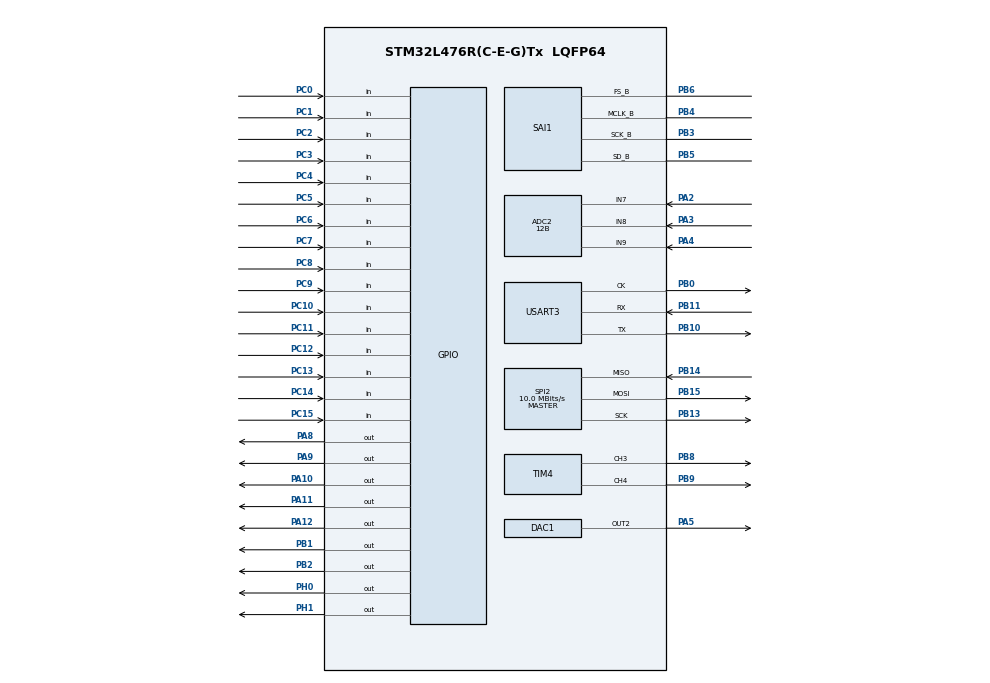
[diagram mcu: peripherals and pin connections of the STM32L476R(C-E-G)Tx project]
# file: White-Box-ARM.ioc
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ADC2.Channel-69\#ChannelRegularConversion=ADC_CHANNEL_9
ADC2.ClockPrescaler=ADC_CLOCK_ASYNC_DIV12
ADC2.ContinuousConvMode=ENABLE
ADC2.DMAContinuousRequests=DISABLE
ADC2.DataAlign=ADC_DATAALIGN_RIGHT
ADC2.DiscontinuousConvMode=DISABLE
ADC2.EOCSelection=ADC_EOC_SINGLE_CONV
ADC2.EnableAnalogWatchDog1=false
ADC2.EnableAnalogWatchDog2=false
ADC2.EnableAnalogWatchDog3=false
ADC2.EnableInjectedConversion=DISABLE
ADC2.EnableRegularConversion=ENABLE
ADC2.ExternalTrigConv=ADC_SOFTWARE_START
ADC2.ExternalTrigConvEdge=ADC_EXTERNALTRIGCONVEDGE_NONE
ADC2.LowPowerAutoWait=DISABLE
ADC2.NbrOfConversion=1
ADC2.NbrOfConversionFlag=1
ADC2.OffsetNumber-69\#ChannelRegularConversion=ADC_OFFSET_NONE
ADC2.Overrun=ADC_OVR_DATA_PRESERVED
ADC2.OversamplingMode=DISABLE
ADC2.Rank-69\#ChannelRegularConversion=1
ADC2.Resolution=ADC_RESOLUTION_12B
ADC2.SamplingTime-69\#ChannelRegularConversion=ADC_SAMPLETIME_2CYCLES_5
ADC2.ScanConvMode=ADC_SCAN_DISABLE
DAC1.DAC_Channel-DAC_OUT2=DAC_CHANNEL_2
Mcu.Family=STM32L4
Mcu.Name=STM32L476R(C-E-G)Tx
Mcu.Package=LQFP64
NVIC.ADC1_2_IRQn=true\:0\:0\:false\:false\:true\:true
NVIC.PriorityGroup=NVIC_PRIORITYGROUP_4
NVIC.TIM4_IRQn=true\:0\:0\:false\:false\:true\:true
NVIC.TIM6_DAC_IRQn=true\:0\:0\:false\:false\:true\:true
PA10.Signal=GPIO_Output
PA11.Signal=GPIO_Output
PA12.Signal=GPIO_Output
PA2.Signal=ADCx_IN7
PA3.Signal=ADCx_IN8
PA4.Signal=ADCx_IN9
PA5.Signal=COMP_DAC12_group
PA8.Signal=GPIO_Output
PA9.Signal=GPIO_Output
PB0.Mode=Synchronous
PB0.Signal=USART3_CK
PB1.GPIO_Speed=GPIO_SPEED_FREQ_LOW
PB1.PinState=GPIO_PIN_RESET
PB1.Signal=GPIO_Output
PB10.Mode=Synchronous
PB10.Signal=USART3_TX
PB11.Mode=Synchronous
PB11.Signal=USART3_RX
PB13.Mode=Full_Duplex_Master
PB13.Signal=SPI2_SCK
PB14.Mode=Full_Duplex_Master
PB14.Signal=SPI2_MISO
PB15.Mode=Full_Duplex_Master
PB15.Signal=SPI2_MOSI
PB2.GPIO_Speed=GPIO_SPEED_FREQ_LOW
PB2.PinState=GPIO_PIN_RESET
PB2.Signal=GPIO_Output
PB3\ (JTDO-TRACESWO).Mode=SAI_B_MasterWithClock
PB3\ (JTDO-TRACESWO).Signal=SAI1_SCK_B
PB4\ (NJTRST).Mode=SAI_B_MasterWithClock
PB4\ (NJTRST).Signal=SAI1_MCLK_B
PB5.Mode=SAI_B_MasterWithClock
PB5.Signal=SAI1_SD_B
PB6.Mode=SAI_B_MasterWithClock
PB6.Signal=SAI1_FS_B
PB8.Signal=S_TIM4_CH3
PB9.Signal=S_TIM4_CH4
PC0.Signal=GPIO_Input
PC1.GPIO_PuPd=GPIO_PULLUP
PC1.Signal=GPIO_Input
PC10.Signal=GPIO_Input
PC11.Signal=GPIO_Input
PC12.Signal=GPIO_Input
PC13.Signal=GPIO_Input
PC14-OSC32_IN\ (PC14).Signal=GPIO_Input
PC15-OSC32_OUT\ (PC15).Signal=GPIO_Input
PC2.GPIO_PuPd=GPIO_PULLUP
PC2.Signal=GPIO_Input
PC3.GPIO_PuPd=GPIO_PULLUP
PC3.Signal=GPIO_Input
PC4.GPIO_PuPd=GPIO_PULLUP
PC4.Signal=GPIO_Input
PC5.GPIO_PuPd=GPIO_PULLUP
PC5.Signal=GPIO_Input
PC6.GPIO_PuPd=GPIO_PULLUP
PC6.Signal=GPIO_Input
PC7.GPIO_PuPd=GPIO_PULLUP
PC7.Signal=GPIO_Input
PC8.Signal=GPIO_Input
PC9.Signal=GPIO_Input
PH0-OSC_IN\ (PH0).GPIO_Speed=GPIO_SPEED_FREQ_LOW
PH0-OSC_IN\ (PH0).PinState=GPIO_PIN_RESET
PH0-OSC_IN\ (PH0).Signal=GPIO_Output
PH1-OSC_OUT\ (PH1).GPIO_Speed=GPIO_SPEED_FREQ_LOW
PH1-OSC_OUT\ (PH1).PinState=GPIO_PIN_RESET
PH1-OSC_OUT\ (PH1).Signal=GPIO_Output
ProjectManager.HeapSize=0x200
ProjectManager.StackSize=0x400
ProjectManager.TargetToolchain=Makefile
RCC.ADCFreq_Value=8000000
RCC.AHBFreq_Value=80000000
RCC.APB1CLKDivider=RCC_HCLK_DIV4
RCC.APB1Freq_Value=20000000
RCC.APB1TimFreq_Value=40000000
RCC.APB2CLKDivider=RCC_HCLK_DIV4
RCC.APB2Freq_Value=20000000
RCC.APB2TimFreq_Value=40000000
RCC.CortexFreq_Value=80000000
RCC.HCLKFreq_Value=80000000
RCC.HSE_VALUE=8000000
RCC.HSI_VALUE=16000000
RCC.LPTIM2CLockSelection=RCC_LPTIM2CLKSOURCE_HSI
RCC.LSE_VALUE=32768
RCC.MSI_VALUE=4000000
RCC.PLLN=40
RCC.PLLSAI1N=16
RCC.PLLSAI1R=RCC_PLLR_DIV8
RCC.PLLSAI2N=28
RCC.SAI1CLockSelection=RCC_SAI1CLKSOURCE_PLLSAI2
RCC.SYSCLKFreq_VALUE=80000000
RCC.SYSCLKSource=RCC_SYSCLKSOURCE_PLLCLK
RCC.USBFreq_Value=32000000
RCC.VCOOutputFreq_Value=160000000
SAI1.AudioFrequency-SAI_B_MasterWithClock=SAI_AUDIO_FREQUENCY_44K
SAI1.ErrorAudioFreq-SAI_B_MasterWithClock=-81.39 %
SAI1.InitProtocol-SAI_B_MasterWithClock=Enable
SAI1.Instance-SAI_B_MasterWithClock=SAI$Index_Block_B
SAI1.MClockEnable-SAI_B_MasterWithClock=SAI_MASTERCLOCK_ENABLE
SAI1.RealAudioFreq-SAI_B_MasterWithClock=35.714 KHz
SAI1.Synchro-SAI_B_MasterWithClock=SAI_ASYNCHRONOUS
SAI1.VirtualMode-SAI_B_MasterWithClock=VM_MASTER
SAI1.VirtualProtocol-SAI_B_BASIC=VM_BASIC_PROTOCOL
SH.ADCx_IN7.0=ADC2_IN7,IN7-Differential
SH.ADCx_IN8.0=ADC2_IN8,IN7-Differential
SH.ADCx_IN9.0=ADC2_IN9,IN9-Single-Ended
SH.COMP_DAC12_group.0=DAC1_OUT2,DAC_OUT2
SH.S_TIM4_CH3.0=TIM4_CH3,PWM Generation3 CH3
SH.S_TIM4_CH4.0=TIM4_CH4,PWM Generation4 CH4
SPI2.CalculateBaudRate=10.0 MBits/s
SPI2.Direction=SPI_DIRECTION_2LINES
SPI2.Mode=SPI_MODE_MASTER
SPI2.VirtualType=VM_MASTER
TIM4.AutoReloadPreload=TIM_AUTORELOAD_PRELOAD_ENABLE
TIM4.Channel-PWM\ Generation3\ CH3=TIM_CHANNEL_3
TIM4.Channel-PWM\ Generation4\ CH4=TIM_CHANNEL_4
TIM4.Pulse-PWM\ Generation3\ CH3=13107
TIM4.Pulse-PWM\ Generation4\ CH4=13107
TIM6.Period=40
TIM6.Prescaler=1000
USART3.VirtualMode-Synchronous=VM_SYNC
VP_SAI1_VP_$IpInstance_SAIB_SAI_BASIC.Mode=SAI_B_BASIC
VP_TIM6_VS_ClockSourceINT.Mode=Enable_Timer
board=White-Box-ARM

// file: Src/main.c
/**
  ******************************************************************************
  * File Name          : main.c
  * Description        : Main program body
  ******************************************************************************
  ** This notice applies to any and all portions of this file
  * that are not between comment pairs USER CODE BEGIN and
  * USER CODE END. Other portions of this file, whether
  * inserted by the user or by software development tools
  * are owned by their respective copyright owners.
  *
  * COPYRIGHT(c) 2017 STMicroelectronics
  *
  * Redistribution and use in source and binary forms, with or without modification,
  * are permitted provided that the following conditions are met:
  *   1. Redistributions of source code must retain the above copyright notice,
  *      this list of conditions and the following disclaimer.
  *   2. Redistributions in binary form must reproduce the above copyright notice,
  *      this list of conditions and the following disclaimer in the documentation
  *      and/or other materials provided with the distribution.
  *   3. Neither the name of STMicroelectronics nor the names of its contributors
  *      may be used to endorse or promote products derived from this software
  *      without specific prior written permission.
  *
  * THIS SOFTWARE IS PROVIDED BY THE COPYRIGHT HOLDERS AND CONTRIBUTORS "AS IS"
  * AND ANY EXPRESS OR IMPLIED WARRANTIES, INCLUDING, BUT NOT LIMITED TO, THE
  * IMPLIED WARRANTIES OF MERCHANTABILITY AND FITNESS FOR A PARTICULAR PURPOSE ARE
  * DISCLAIMED. IN NO EVENT SHALL THE COPYRIGHT HOLDER OR CONTRIBUTORS BE LIABLE
  * FOR ANY DIRECT, INDIRECT, INCIDENTAL, SPECIAL, EXEMPLARY, OR CONSEQUENTIAL
  * DAMAGES (INCLUDING, BUT NOT LIMITED TO, PROCUREMENT OF SUBSTITUTE GOODS OR
  * SERVICES; LOSS OF USE, DATA, OR PROFITS; OR BUSINESS INTERRUPTION) HOWEVER
  * CAUSED AND ON ANY THEORY OF LIABILITY, WHETHER IN CONTRACT, STRICT LIABILITY,
  * OR TORT (INCLUDING NEGLIGENCE OR OTHERWISE) ARISING IN ANY WAY OUT OF THE USE
  * OF THIS SOFTWARE, EVEN IF ADVISED OF THE POSSIBILITY OF SUCH DAMAGE.
  *
  ******************************************************************************
  */
#include "main.h"
#include "stm32l4xx_hal.h"

/* USER CODE BEGIN Includes */
#include "math.h"
#include "lcd.h"
#include "effects.h"
/* USER CODE END Includes */

SAI_HandleTypeDef hsai_BlockB1;

TIM_HandleTypeDef htim6;

/* USER CODE BEGIN PV */
/* Private variables ---------------------------------------------------------*/

/* USER CODE END PV */

void SystemClock_Config(void);
static void MX_GPIO_Init(void);
static void MX_SAI1_Init(void);
static void MX_TIM4_Init(void);
static void MX_ADC2_Init(void);
static void MX_SPI2_Init(void);
static void MX_USART3_Init(void);
static void MX_DAC1_Init(void);
static void MX_TIM6_Init(void);

/* USER CODE BEGIN PFP */
/* Private function prototypes -----------------------------------------------*/

/* USER CODE END PFP */

int main(void)
{

  /* MCU Configuration----------------------------------------------------------*/

  /* Reset of all peripherals, Initializes the Flash interface and the Systick. */
  HAL_Init();

  /* Configure the system clock */
  SystemClock_Config();

  /* Initialize all configured peripherals */
  MX_GPIO_Init();
  MX_SAI1_Init();
  MX_TIM4_Init();
  MX_ADC2_Init();
  MX_SPI2_Init();
  MX_USART3_Init();
  MX_DAC1_Init();
  MX_TIM6_Init();

  /* USER CODE BEGIN 2 */
  init_LCD();
  effects_init();

  unsigned int i;
  char line1[] = "current count:      ";
  for(i = 0; i < LCD_line_length; i++){
    LCD_write_data(line1[i]);
  }

  while (1) {
    LCD_write_integer(1, 15, i, 5);

  }
  /* USER CODE END 2 */

  /* Infinite loop */
  while (1)
  {

  }

}

/** System Clock Configuration
*/
void SystemClock_Config(void)
{

  LL_FLASH_SetLatency(LL_FLASH_LATENCY_3);

  if(LL_FLASH_GetLatency() != LL_FLASH_LATENCY_3)
  {
  Error_Handler();
  }
  LL_PWR_SetRegulVoltageScaling(LL_PWR_REGU_VOLTAGE_SCALE1);

  LL_RCC_MSI_Enable();

   /* Wait till MSI is ready */
  while(LL_RCC_MSI_IsReady() != 1)
  {

  }
  LL_RCC_MSI_EnableRangeSelection();

  LL_RCC_MSI_SetRange(LL_RCC_MSIRANGE_6);

  LL_RCC_MSI_SetCalibTrimming(0);

  LL_RCC_PLL_ConfigDomain_SYS(LL_RCC_PLLSOURCE_MSI, LL_RCC_PLLM_DIV_1, 40, LL_RCC_PLLR_DIV_2);

  LL_RCC_PLL_EnableDomain_SYS();

  LL_RCC_PLL_Enable();

   /* Wait till PLL is ready */
  while(LL_RCC_PLL_IsReady() != 1)
  {

  }
  LL_RCC_PLLSAI1_ConfigDomain_ADC(LL_RCC_PLLSOURCE_MSI, LL_RCC_PLLM_DIV_1, 16, LL_RCC_PLLSAI1R_DIV_8);

  LL_RCC_PLLSAI1_EnableDomain_ADC();

  LL_RCC_PLLSAI1_Enable();

   /* Wait till PLLSAI1 is ready */
  while(LL_RCC_PLLSAI1_IsReady() != 1)
  {

  }
  LL_RCC_PLLSAI2_ConfigDomain_SAI(LL_RCC_PLLSOURCE_MSI, LL_RCC_PLLM_DIV_1, 28, LL_RCC_PLLSAI2P_DIV_7);

  LL_RCC_PLLSAI2_EnableDomain_SAI();

  LL_RCC_PLLSAI2_Enable();

   /* Wait till PLLSAI2 is ready */
  while(LL_RCC_PLLSAI2_IsReady() != 1)
  {

  }
  LL_RCC_SetSysClkSource(LL_RCC_SYS_CLKSOURCE_PLL);

   /* Wait till System clock is ready */
  while(LL_RCC_GetSysClkSource() != LL_RCC_SYS_CLKSOURCE_STATUS_PLL)
  {

  }
  LL_RCC_SetAHBPrescaler(LL_RCC_SYSCLK_DIV_1);

  LL_RCC_SetAPB1Prescaler(LL_RCC_APB1_DIV_4);

  LL_RCC_SetAPB2Prescaler(LL_RCC_APB2_DIV_4);

  LL_Init1msTick(80000000);

  LL_SYSTICK_SetClkSource(LL_SYSTICK_CLKSOURCE_HCLK);

  LL_SetSystemCoreClock(80000000);

  LL_RCC_SetUSARTClockSource(LL_RCC_USART3_CLKSOURCE_PCLK1);

  LL_RCC_SetSAIClockSource(LL_RCC_SAI1_CLKSOURCE_PLLSAI2);

  LL_RCC_SetADCClockSource(LL_RCC_ADC_CLKSOURCE_PLLSAI1);

  /* SysTick_IRQn interrupt configuration */
  NVIC_SetPriority(SysTick_IRQn, NVIC_EncodePriority(NVIC_GetPriorityGrouping(),0, 0));
}

/* ADC2 init function */
static void MX_ADC2_Init(void)
{

  LL_ADC_InitTypeDef ADC_InitStruct;
  LL_ADC_REG_InitTypeDef ADC_REG_InitStruct;
  LL_ADC_CommonInitTypeDef ADC_CommonInitStruct;

  LL_GPIO_InitTypeDef GPIO_InitStruct;

  /* Peripheral clock enable */
  LL_AHB2_GRP1_EnableClock(LL_AHB2_GRP1_PERIPH_ADC);

  /**ADC2 GPIO Configuration
  PA2   ------> ADC2_IN7
  PA3   ------> ADC2_IN8
  PA4   ------> ADC2_IN9
  */
  GPIO_InitStruct.Pin = LL_GPIO_PIN_2|LL_GPIO_PIN_3|LL_GPIO_PIN_4;
  GPIO_InitStruct.Mode = LL_GPIO_MODE_ANALOG;
  GPIO_InitStruct.Pull = LL_GPIO_PULL_NO;
  LL_GPIO_Init(GPIOA, &GPIO_InitStruct);

  LL_GPIO_EnablePinAnalogControl(GPIOA, LL_GPIO_PIN_2|LL_GPIO_PIN_3|LL_GPIO_PIN_4);

  /* ADC2 interrupt Init */
  NVIC_SetPriority(ADC1_2_IRQn, NVIC_EncodePriority(NVIC_GetPriorityGrouping(),0, 0));
  NVIC_EnableIRQ(ADC1_2_IRQn);

    /**Common config
    */
  ADC_InitStruct.Resolution = LL_ADC_RESOLUTION_12B;
  ADC_InitStruct.DataAlignment = LL_ADC_DATA_ALIGN_RIGHT;
  ADC_InitStruct.LowPowerMode = LL_ADC_LP_MODE_NONE;
  LL_ADC_Init(ADC2, &ADC_InitStruct);

  ADC_REG_InitStruct.TriggerSource = LL_ADC_REG_TRIG_SOFTWARE;
  ADC_REG_InitStruct.SequencerLength = LL_ADC_REG_SEQ_SCAN_DISABLE;
  ADC_REG_InitStruct.SequencerDiscont = LL_ADC_REG_SEQ_DISCONT_DISABLE;
  ADC_REG_InitStruct.ContinuousMode = LL_ADC_REG_CONV_CONTINUOUS;
  ADC_REG_InitStruct.DMATransfer = LL_ADC_REG_DMA_TRANSFER_LIMITED;
  ADC_REG_InitStruct.Overrun = LL_ADC_REG_OVR_DATA_PRESERVED;
  LL_ADC_REG_Init(ADC2, &ADC_REG_InitStruct);

  LL_ADC_SetOverSamplingScope(ADC2, LL_ADC_OVS_DISABLE);

  ADC_CommonInitStruct.CommonClock = LL_ADC_CLOCK_ASYNC_DIV12;
  LL_ADC_CommonInit(__LL_ADC_COMMON_INSTANCE(ADC2), &ADC_CommonInitStruct);

  LL_ADC_EnableIT_EOC(ADC2);

  LL_ADC_DisableIT_EOS(ADC2);

    /**Configure Regular Channel
    */
  LL_ADC_REG_SetSequencerRanks(ADC2, LL_ADC_REG_RANK_1, LL_ADC_CHANNEL_9);

  LL_ADC_SetChannelSamplingTime(ADC2, LL_ADC_CHANNEL_9, LL_ADC_SAMPLINGTIME_2CYCLES_5);

  LL_ADC_SetChannelSingleDiff(ADC2, LL_ADC_CHANNEL_9, LL_ADC_SINGLE_ENDED);

}

/* DAC1 init function */
static void MX_DAC1_Init(void)
{

  LL_DAC_InitTypeDef DAC_InitStruct;

  LL_GPIO_InitTypeDef GPIO_InitStruct;

  /* Peripheral clock enable */
  LL_APB1_GRP1_EnableClock(LL_APB1_GRP1_PERIPH_DAC1);

  /**DAC1 GPIO Configuration
  PA5   ------> DAC1_OUT2
  */
  GPIO_InitStruct.Pin = LL_GPIO_PIN_5;
  GPIO_InitStruct.Mode = LL_GPIO_MODE_ANALOG;
  GPIO_InitStruct.Pull = LL_GPIO_PULL_NO;
  LL_GPIO_Init(GPIOA, &GPIO_InitStruct);

  /* DAC1 interrupt Init */
  NVIC_SetPriority(TIM6_DAC_IRQn, NVIC_EncodePriority(NVIC_GetPriorityGrouping(),0, 0));
  NVIC_EnableIRQ(TIM6_DAC_IRQn);

    /**DAC channel OUT2 config
    */
  DAC_InitStruct.TriggerSource = LL_DAC_TRIG_SOFTWARE;
  DAC_InitStruct.WaveAutoGeneration = LL_DAC_WAVE_AUTO_GENERATION_NONE;
  DAC_InitStruct.OutputBuffer = LL_DAC_OUTPUT_BUFFER_ENABLE;
  DAC_InitStruct.OutputConnection = LL_DAC_OUTPUT_CONNECT_GPIO;
  DAC_InitStruct.OutputMode = LL_DAC_OUTPUT_MODE_NORMAL;
  LL_DAC_Init(DAC1, LL_DAC_CHANNEL_2, &DAC_InitStruct);

  LL_DAC_DisableTrigger(DAC1, LL_DAC_CHANNEL_2);

}

/* SAI1 init function */
static void MX_SAI1_Init(void)
{

  hsai_BlockB1.Instance = SAI1_Block_B;
  hsai_BlockB1.Init.AudioMode = SAI_MODEMASTER_TX;
  hsai_BlockB1.Init.Synchro = SAI_ASYNCHRONOUS;
  hsai_BlockB1.Init.OutputDrive = SAI_OUTPUTDRIVE_DISABLE;
  hsai_BlockB1.Init.NoDivider = SAI_MASTERDIVIDER_ENABLE;
  hsai_BlockB1.Init.FIFOThreshold = SAI_FIFOTHRESHOLD_EMPTY;
  hsai_BlockB1.Init.AudioFrequency = SAI_AUDIO_FREQUENCY_44K;
  hsai_BlockB1.Init.SynchroExt = SAI_SYNCEXT_DISABLE;
  hsai_BlockB1.Init.MonoStereoMode = SAI_STEREOMODE;
  hsai_BlockB1.Init.CompandingMode = SAI_NOCOMPANDING;
  hsai_BlockB1.Init.TriState = SAI_OUTPUT_NOTRELEASED;
  if (HAL_SAI_InitProtocol(&hsai_BlockB1, SAI_I2S_STANDARD, SAI_PROTOCOL_DATASIZE_16BIT, 2) != HAL_OK)
  {
    _Error_Handler(__FILE__, __LINE__);
  }

}

/* SPI2 init function */
static void MX_SPI2_Init(void)
{

  LL_SPI_InitTypeDef SPI_InitStruct;

  LL_GPIO_InitTypeDef GPIO_InitStruct;

  /* Peripheral clock enable */
  LL_APB1_GRP1_EnableClock(LL_APB1_GRP1_PERIPH_SPI2);

  /**SPI2 GPIO Configuration
  PB13   ------> SPI2_SCK
  PB14   ------> SPI2_MISO
  PB15   ------> SPI2_MOSI
  */
  GPIO_InitStruct.Pin = LL_GPIO_PIN_13|LL_GPIO_PIN_14|LL_GPIO_PIN_15;
  GPIO_InitStruct.Mode = LL_GPIO_MODE_ALTERNATE;
  GPIO_InitStruct.Speed = LL_GPIO_SPEED_FREQ_VERY_HIGH;
  GPIO_InitStruct.OutputType = LL_GPIO_OUTPUT_PUSHPULL;
  GPIO_InitStruct.Pull = LL_GPIO_PULL_NO;
  GPIO_InitStruct.Alternate = LL_GPIO_AF_5;
  LL_GPIO_Init(GPIOB, &GPIO_InitStruct);

  /* SPI2 parameter configuration*/
  SPI_InitStruct.TransferDirection = LL_SPI_FULL_DUPLEX;
  SPI_InitStruct.Mode = LL_SPI_MODE_MASTER;
  SPI_InitStruct.DataWidth = LL_SPI_DATAWIDTH_4BIT;
  SPI_InitStruct.ClockPolarity = LL_SPI_POLARITY_LOW;
  SPI_InitStruct.ClockPhase = LL_SPI_PHASE_1EDGE;
  SPI_InitStruct.NSS = LL_SPI_NSS_SOFT;
  SPI_InitStruct.BaudRate = LL_SPI_BAUDRATEPRESCALER_DIV2;
  SPI_InitStruct.BitOrder = LL_SPI_MSB_FIRST;
  SPI_InitStruct.CRCCalculation = LL_SPI_CRCCALCULATION_DISABLE;
  SPI_InitStruct.CRCPoly = 7;
  LL_SPI_Init(SPI2, &SPI_InitStruct);

  LL_SPI_SetStandard(SPI2, LL_SPI_PROTOCOL_MOTOROLA);

  LL_SPI_EnableNSSPulseMgt(SPI2);

}

/* TIM4 init function */
static void MX_TIM4_Init(void)
{

  LL_TIM_InitTypeDef TIM_InitStruct;
  LL_TIM_OC_InitTypeDef TIM_OC_InitStruct;

  LL_GPIO_InitTypeDef GPIO_InitStruct;

  /* Peripheral clock enable */
  LL_APB1_GRP1_EnableClock(LL_APB1_GRP1_PERIPH_TIM4);

  /* TIM4 interrupt Init */
  NVIC_SetPriority(TIM4_IRQn, NVIC_EncodePriority(NVIC_GetPriorityGrouping(),0, 0));
  NVIC_EnableIRQ(TIM4_IRQn);

  TIM_InitStruct.Prescaler = 0;
  TIM_InitStruct.CounterMode = LL_TIM_COUNTERMODE_UP;
  TIM_InitStruct.Autoreload = 0;
  TIM_InitStruct.ClockDivision = LL_TIM_CLOCKDIVISION_DIV1;
  LL_TIM_Init(TIM4, &TIM_InitStruct);

  LL_TIM_EnableARRPreload(TIM4);

  LL_TIM_OC_EnablePreload(TIM4, LL_TIM_CHANNEL_CH3);

  TIM_OC_InitStruct.OCMode = LL_TIM_OCMODE_PWM1;
  TIM_OC_InitStruct.OCState = LL_TIM_OCSTATE_DISABLE;
  TIM_OC_InitStruct.OCNState = LL_TIM_OCSTATE_DISABLE;
  TIM_OC_InitStruct.CompareValue = 13107;
  TIM_OC_InitStruct.OCPolarity = LL_TIM_OCPOLARITY_HIGH;
  LL_TIM_OC_Init(TIM4, LL_TIM_CHANNEL_CH3, &TIM_OC_InitStruct);

  LL_TIM_OC_DisableFast(TIM4, LL_TIM_CHANNEL_CH3);

  LL_TIM_OC_EnablePreload(TIM4, LL_TIM_CHANNEL_CH4);

  TIM_OC_InitStruct.OCState = LL_TIM_OCSTATE_DISABLE;
  TIM_OC_InitStruct.OCNState = LL_TIM_OCSTATE_DISABLE;
  LL_TIM_OC_Init(TIM4, LL_TIM_CHANNEL_CH4, &TIM_OC_InitStruct);

  LL_TIM_OC_DisableFast(TIM4, LL_TIM_CHANNEL_CH4);

  LL_TIM_SetOCRefClearInputSource(TIM4, LL_TIM_OCREF_CLR_INT_NC);

  LL_TIM_DisableExternalClock(TIM4);

  LL_TIM_ConfigETR(TIM4, LL_TIM_ETR_POLARITY_NONINVERTED, LL_TIM_ETR_PRESCALER_DIV1, LL_TIM_ETR_FILTER_FDIV1);

  LL_TIM_SetTriggerOutput(TIM4, LL_TIM_TRGO_RESET);

  LL_TIM_DisableMasterSlaveMode(TIM4);

  /**TIM4 GPIO Configuration
  PB8   ------> TIM4_CH3
  PB9   ------> TIM4_CH4
  */
  GPIO_InitStruct.Pin = LL_GPIO_PIN_8|LL_GPIO_PIN_9;
  GPIO_InitStruct.Mode = LL_GPIO_MODE_ALTERNATE;
  GPIO_InitStruct.Speed = LL_GPIO_SPEED_FREQ_LOW;
  GPIO_InitStruct.OutputType = LL_GPIO_OUTPUT_PUSHPULL;
  GPIO_InitStruct.Pull = LL_GPIO_PULL_NO;
  GPIO_InitStruct.Alternate = LL_GPIO_AF_2;
  LL_GPIO_Init(GPIOB, &GPIO_InitStruct);

}

/* TIM6 init function */
static void MX_TIM6_Init(void)
{

  TIM_MasterConfigTypeDef sMasterConfig;

  htim6.Instance = TIM6;
  htim6.Init.Prescaler = 1000;
  htim6.Init.CounterMode = TIM_COUNTERMODE_UP;
  htim6.Init.Period = 40;
  htim6.Init.AutoReloadPreload = TIM_AUTORELOAD_PRELOAD_DISABLE;
  if (HAL_TIM_Base_Init(&htim6) != HAL_OK)
  {
    _Error_Handler(__FILE__, __LINE__);
  }

  sMasterConfig.MasterOutputTrigger = TIM_TRGO_RESET;
  sMasterConfig.MasterSlaveMode = TIM_MASTERSLAVEMODE_DISABLE;
  if (HAL_TIMEx_MasterConfigSynchronization(&htim6, &sMasterConfig) != HAL_OK)
  {
    _Error_Handler(__FILE__, __LINE__);
  }

}

/* USART3 init function */
static void MX_USART3_Init(void)
{

  LL_USART_InitTypeDef USART_InitStruct;
  LL_USART_ClockInitTypeDef USART_ClockInitStruct;

  LL_GPIO_InitTypeDef GPIO_InitStruct;

  /* Peripheral clock enable */
  LL_APB1_GRP1_EnableClock(LL_APB1_GRP1_PERIPH_USART3);

  /**USART3 GPIO Configuration
  PB0   ------> USART3_CK
  PB10   ------> USART3_TX
  PB11   ------> USART3_RX
  */
  GPIO_InitStruct.Pin = LL_GPIO_PIN_0|LL_GPIO_PIN_10|LL_GPIO_PIN_11;
  GPIO_InitStruct.Mode = LL_GPIO_MODE_ALTERNATE;
  GPIO_InitStruct.Speed = LL_GPIO_SPEED_FREQ_VERY_HIGH;
  GPIO_InitStruct.OutputType = LL_GPIO_OUTPUT_PUSHPULL;
  GPIO_InitStruct.Pull = LL_GPIO_PULL_NO;
  GPIO_InitStruct.Alternate = LL_GPIO_AF_7;
  LL_GPIO_Init(GPIOB, &GPIO_InitStruct);

  USART_InitStruct.BaudRate = 115200;
  USART_InitStruct.DataWidth = LL_USART_DATAWIDTH_7B;
  USART_InitStruct.StopBits = LL_USART_STOPBITS_1;
  USART_InitStruct.Parity = LL_USART_PARITY_NONE;
  USART_InitStruct.TransferDirection = LL_USART_DIRECTION_TX_RX;
  USART_InitStruct.OverSampling = LL_USART_OVERSAMPLING_8;

  LL_USART_Init(USART3, &USART_InitStruct);

  USART_ClockInitStruct.ClockPolarity = LL_USART_POLARITY_LOW;
  USART_ClockInitStruct.ClockPhase = LL_USART_PHASE_1EDGE;
  USART_ClockInitStruct.LastBitClockPulse = LL_USART_LASTCLKPULSE_NO_OUTPUT;
  LL_USART_ClockInit(USART3, &USART_ClockInitStruct);

  LL_USART_ConfigSyncMode(USART3);

  LL_USART_Enable(USART3);

}

/** Configure pins as
        * Analog
        * Input
        * Output
        * EVENT_OUT
        * EXTI
*/
static void MX_GPIO_Init(void)
{

  LL_GPIO_InitTypeDef GPIO_InitStruct;

  /* GPIO Ports Clock Enable */
  LL_AHB2_GRP1_EnableClock(LL_AHB2_GRP1_PERIPH_GPIOC);
  LL_AHB2_GRP1_EnableClock(LL_AHB2_GRP1_PERIPH_GPIOH);
  LL_AHB2_GRP1_EnableClock(LL_AHB2_GRP1_PERIPH_GPIOA);
  LL_AHB2_GRP1_EnableClock(LL_AHB2_GRP1_PERIPH_GPIOB);

  /**/
  LL_GPIO_ResetOutputPin(GPIOH, LL_GPIO_PIN_0|LL_GPIO_PIN_1);

  /**/
  LL_GPIO_ResetOutputPin(GPIOB, LL_GPIO_PIN_1|LL_GPIO_PIN_2);

  /**/
  LL_GPIO_ResetOutputPin(GPIOA, LL_GPIO_PIN_8|LL_GPIO_PIN_9|LL_GPIO_PIN_10|LL_GPIO_PIN_11
                          |LL_GPIO_PIN_12);

  /**/
  GPIO_InitStruct.Pin = LL_GPIO_PIN_13|LL_GPIO_PIN_14|LL_GPIO_PIN_15|LL_GPIO_PIN_0
                          |LL_GPIO_PIN_8|LL_GPIO_PIN_9|LL_GPIO_PIN_10|LL_GPIO_PIN_11
                          |LL_GPIO_PIN_12;
  GPIO_InitStruct.Mode = LL_GPIO_MODE_INPUT;
  GPIO_InitStruct.Pull = LL_GPIO_PULL_NO;
  LL_GPIO_Init(GPIOC, &GPIO_InitStruct);

  /**/
  GPIO_InitStruct.Pin = LL_GPIO_PIN_0|LL_GPIO_PIN_1;
  GPIO_InitStruct.Mode = LL_GPIO_MODE_OUTPUT;
  GPIO_InitStruct.Speed = LL_GPIO_SPEED_FREQ_LOW;
  GPIO_InitStruct.OutputType = LL_GPIO_OUTPUT_PUSHPULL;
  GPIO_InitStruct.Pull = LL_GPIO_PULL_NO;
  LL_GPIO_Init(GPIOH, &GPIO_InitStruct);

  /**/
  GPIO_InitStruct.Pin = LL_GPIO_PIN_1|LL_GPIO_PIN_2|LL_GPIO_PIN_3|LL_GPIO_PIN_4
                          |LL_GPIO_PIN_5|LL_GPIO_PIN_6|LL_GPIO_PIN_7;
  GPIO_InitStruct.Mode = LL_GPIO_MODE_INPUT;
  GPIO_InitStruct.Pull = LL_GPIO_PULL_UP;
  LL_GPIO_Init(GPIOC, &GPIO_InitStruct);

  /**/
  GPIO_InitStruct.Pin = LL_GPIO_PIN_1|LL_GPIO_PIN_2;
  GPIO_InitStruct.Mode = LL_GPIO_MODE_OUTPUT;
  GPIO_InitStruct.Speed = LL_GPIO_SPEED_FREQ_LOW;
  GPIO_InitStruct.OutputType = LL_GPIO_OUTPUT_PUSHPULL;
  GPIO_InitStruct.Pull = LL_GPIO_PULL_NO;
  LL_GPIO_Init(GPIOB, &GPIO_InitStruct);

  /**/
  GPIO_InitStruct.Pin = LL_GPIO_PIN_8|LL_GPIO_PIN_9|LL_GPIO_PIN_10|LL_GPIO_PIN_11
                          |LL_GPIO_PIN_12;
  GPIO_InitStruct.Mode = LL_GPIO_MODE_OUTPUT;
  GPIO_InitStruct.Speed = LL_GPIO_SPEED_FREQ_LOW;
  GPIO_InitStruct.OutputType = LL_GPIO_OUTPUT_PUSHPULL;
  GPIO_InitStruct.Pull = LL_GPIO_PULL_NO;
  LL_GPIO_Init(GPIOA, &GPIO_InitStruct);

}

void _Error_Handler(char * file, int line)
{
  /* USER CODE BEGIN Error_Handler_Debug */
  /* User can add his own implementation to report the HAL error return state */
  while(1)
  {
    printf("%s\n%d",file, line);
    return;
  }
  /* USER CODE END Error_Handler_Debug */
}

/************************ (C) COPYRIGHT STMicroelectronics *****END OF FILE****/
